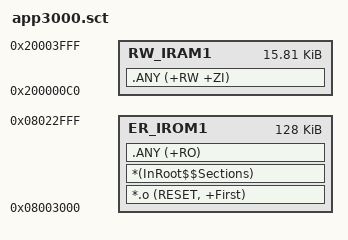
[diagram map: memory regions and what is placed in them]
; *************************************************************
; *** Scatter-Loading Description File generated by uVision ***
; *************************************************************

;LR_IROM1 0x08000000 0x00020000  {    ; load region size_region
;   ER_IROM1 0x08000000 0x00020000  {  ; load address = execution address
LR_IROM1 0x08003000 0x00020000  {    ; load region size_region
  ER_IROM1 0x08003000 0x00020000  {  ; load address = execution address
   *.o (RESET, +First)
   *(InRoot$$Sections)
   .ANY (+RO)
  }
  RW_IRAM1 0x200000C0 0x00003F40  {  ; RW data
   .ANY (+RW +ZI)
  }
}

